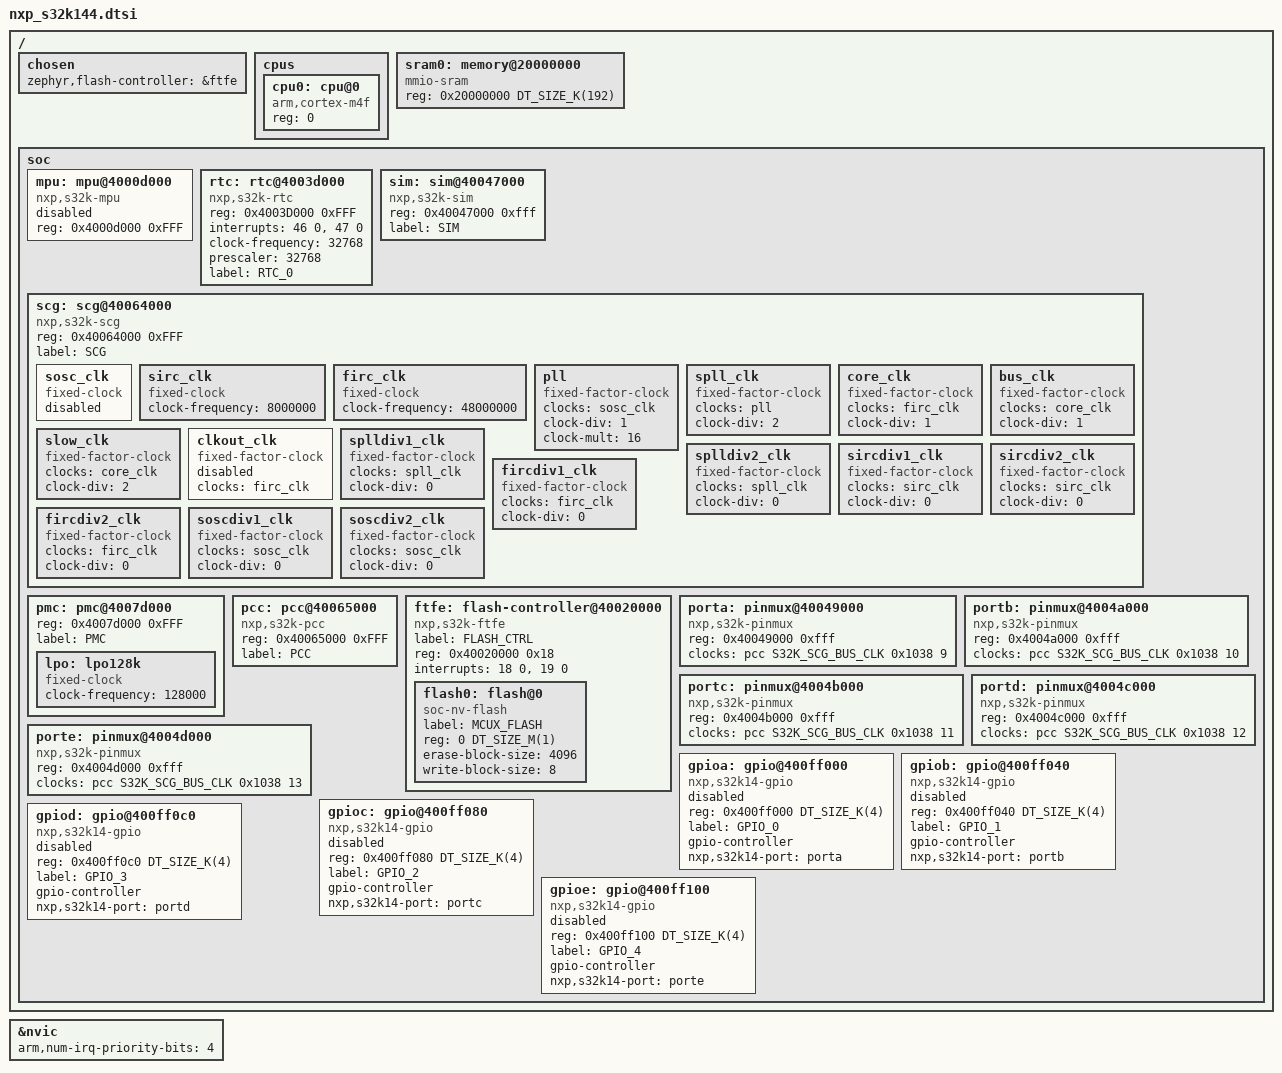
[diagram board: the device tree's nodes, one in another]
/*
 * Copyright (c) 2021, Dung Tran
 *
 * SPDX-License-Identifier: Apache-2.0
 */

#include <mem.h>
#include <arm/armv7-m.dtsi>
#include <dt-bindings/clock/s32k_clock.h>
#include <dt-bindings/gpio/gpio.h>

/ {
	chosen {
		zephyr,flash-controller = &ftfe;
	};

	cpus {
		#address-cells = <1>;
		#size-cells = <0>;

		cpu0: cpu@0 {
			device_type = "cpu";
			compatible = "arm,cortex-m4f";
			reg = <0>;
		};
	};

	sram0: memory@20000000 {
		compatible = "mmio-sram";
		reg = <0x20000000 DT_SIZE_K(192)>;
	};

	soc {
		mpu: mpu@4000d000 {
			compatible = "nxp,s32k-mpu";
			reg = <0x4000d000 0xFFF>;
			status = "disabled";
		};

		rtc: rtc@4003d000 {
			compatible = "nxp,s32k-rtc";
			reg = <0x4003D000 0xFFF>;
			interrupts = <46 0>, <47 0>;
			interrupt-names = "alarm", "seconds";
			clock-frequency = <32768>;
			prescaler = <32768>;
			label = "RTC_0";
		};

		sim: sim@40047000 {
			compatible = "nxp,s32k-sim";
			reg = <0x40047000 0xfff>;
			label = "SIM";
			#clock-cells = <3>;
		};

		scg: scg@40064000 {
			compatible = "nxp,s32k-scg";
			reg = <0x40064000 0xFFF>;
			label = "SCG";
			#clock-cells = <1>;

			sosc_clk: sosc_clk {
				compatible = "fixed-clock";
				status = "disabled";
				#clock-cells = <0>;
			};

			sirc_clk: sirc_clk {
				compatible = "fixed-clock";
				clock-frequency = <8000000>;
				#clock-cells = <0>;
			};

			firc_clk: firc_clk {
				compatible = "fixed-clock";
				clock-frequency = <48000000>;
				#clock-cells = <0>;
			};

			pll: pll {
				compatible = "fixed-factor-clock";
				clocks = <&sosc_clk>;
				clock-div = <1>;
				clock-mult = <16>;
				#clock-cells = <0>;
			};

			spll_clk: spll_clk {
				compatible = "fixed-factor-clock";
				clocks = <&pll>;
				clock-div = <2>;
				#clock-cells = <0>;
			};

			core_clk: core_clk {
				compatible = "fixed-factor-clock";
				clocks = <&firc_clk>;
				clock-div = <1>;
				#clock-cells = <0>;
			};

			bus_clk: bus_clk {
				compatible = "fixed-factor-clock";
				clocks = <&core_clk>;
				clock-div = <1>;
				#clock-cells = <0>;
			};

			slow_clk: slow_clk {
				compatible = "fixed-factor-clock";
				clocks = <&core_clk>;
				clock-div = <2>;
				#clock-cells = <0>;
			};

			clkout_clk: clkout_clk {
				compatible = "fixed-factor-clock";
				status = "disabled";
				clocks = <&firc_clk>;
				#clock-cells = <0>;
			};

			splldiv1_clk: splldiv1_clk {
				compatible = "fixed-factor-clock";
				clocks = <&spll_clk>;
				clock-div = <0>;
				#clock-cells = <0>;
			};

			splldiv2_clk: splldiv2_clk {
				compatible = "fixed-factor-clock";
				clocks = <&spll_clk>;
				clock-div = <0>;
				#clock-cells = <0>;
			};

			sircdiv1_clk: sircdiv1_clk {
				compatible = "fixed-factor-clock";
				clocks = <&sirc_clk>;
				clock-div = <0>;
				#clock-cells = <0>;
			};

			sircdiv2_clk: sircdiv2_clk {
				compatible = "fixed-factor-clock";
				clocks = <&sirc_clk>;
				clock-div = <0>;
				#clock-cells = <0>;
			};

			fircdiv1_clk: fircdiv1_clk {
				compatible = "fixed-factor-clock";
				clocks = <&firc_clk>;
				clock-div = <0>;
				#clock-cells = <0>;
			};

			fircdiv2_clk: fircdiv2_clk {
				compatible = "fixed-factor-clock";
				clocks = <&firc_clk>;
				clock-div = <0>;
				#clock-cells = <0>;
			};

			soscdiv1_clk: soscdiv1_clk {
				compatible = "fixed-factor-clock";
				clocks = <&sosc_clk>;
				clock-div = <0>;
				#clock-cells = <0>;
			};

			soscdiv2_clk: soscdiv2_clk {
				compatible = "fixed-factor-clock";
				clocks = <&sosc_clk>;
				clock-div = <0>;
				#clock-cells = <0>;
			};
		};

		pmc: pmc@4007d000 {
			reg = <0x4007d000 0xFFF>;
			label = "PMC";

			lpo: lpo128k {
			/* LPO clock */
				compatible = "fixed-clock";
				clock-frequency = <128000>;
				#clock-cells = <0>;
			};
		};

		pcc: pcc@40065000 {
			compatible = "nxp,s32k-pcc";
			reg = <0x40065000 0xFFF>;
			label = "PCC";
			#clock-cells = <2>;
		};

		ftfe: flash-controller@40020000 {
			compatible = "nxp,s32k-ftfe";
			label = "FLASH_CTRL";
			reg = <0x40020000 0x18>;
			interrupts = <18 0>, <19 0>;
			interrupt-names = "command-complete", "read-collision";

			#address-cells = <1>;
			#size-cells = <1>;

			flash0: flash@0 {
				compatible = "soc-nv-flash";
				label = "MCUX_FLASH";
				reg = <0 DT_SIZE_M(1)>;
				erase-block-size = <4096>;
				write-block-size = <8>;
			};
		};

		porta: pinmux@40049000 {
			compatible = "nxp,s32k-pinmux";
			reg = <0x40049000 0xfff>;
			clocks = <&pcc S32K_SCG_BUS_CLK 0x1038 9>;
		};

		portb: pinmux@4004a000 {
			compatible = "nxp,s32k-pinmux";
			reg = <0x4004a000 0xfff>;
			clocks = <&pcc S32K_SCG_BUS_CLK 0x1038 10>;
		};

		portc: pinmux@4004b000 {
			compatible = "nxp,s32k-pinmux";
			reg = <0x4004b000 0xfff>;
			clocks = <&pcc S32K_SCG_BUS_CLK 0x1038 11>;
		};

		portd: pinmux@4004c000 {
			compatible = "nxp,s32k-pinmux";
			reg = <0x4004c000 0xfff>;
			clocks = <&pcc S32K_SCG_BUS_CLK 0x1038 12>;
		};

		porte: pinmux@4004d000 {
			compatible = "nxp,s32k-pinmux";
			reg = <0x4004d000 0xfff>;
			clocks = <&pcc S32K_SCG_BUS_CLK 0x1038 13>;
		};

		gpioa: gpio@400ff000 {
			compatible = "nxp,s32k14-gpio";
			status = "disabled";
			reg = <0x400ff000 DT_SIZE_K(4)>;
			label = "GPIO_0";
			gpio-controller;
			#gpio-cells = <2>;
			nxp,s32k14-port = <&porta>;
		};

		gpiob: gpio@400ff040 {
			compatible = "nxp,s32k14-gpio";
			status = "disabled";
			reg = <0x400ff040 DT_SIZE_K(4)>;
			label = "GPIO_1";
			gpio-controller;
			#gpio-cells = <2>;
			nxp,s32k14-port = <&portb>;
		};

		gpioc: gpio@400ff080 {
			compatible = "nxp,s32k14-gpio";
			status = "disabled";
			reg = <0x400ff080 DT_SIZE_K(4)>;
			label = "GPIO_2";
			gpio-controller;
			#gpio-cells = <2>;
			nxp,s32k14-port = <&portc>;
		};

		gpiod: gpio@400ff0c0 {
			compatible = "nxp,s32k14-gpio";
			status = "disabled";
			reg = <0x400ff0c0 DT_SIZE_K(4)>;
			label = "GPIO_3";
			gpio-controller;
			#gpio-cells = <2>;
			nxp,s32k14-port = <&portd>;
		};

		gpioe: gpio@400ff100 {
			compatible = "nxp,s32k14-gpio";
			status = "disabled";
			reg = <0x400ff100 DT_SIZE_K(4)>;
			label = "GPIO_4";
			gpio-controller;
			#gpio-cells = <2>;
			nxp,s32k14-port = <&porte>;
		};

		// ftm0: ftm@40038000{
		// 	compatible = "nxp,s32k-ftm";
		// 	reg = <0x40038000 0xFFF>;
		// 	interrupts = <42 0>;
		// 	clocks = <&pcc KINETIS_MCG_FIXED_FREQ_CLK>;
		// 	prescaler = <16>;
		// 	label = "FTM_0";
		// 	status = "disabled";
		// };

		// ftm1: ftm@40039000{
		// 	compatible = "nxp,s32k-ftm";
		// 	reg = <0x40039000 0xFFF>;
		// 	interrupts = <42 0>;
		// 	clocks = <&pcc KINETIS_MCG_FIXED_FREQ_CLK>;
		// 	prescaler = <16>;
		// 	label = "FTM_1";
		// 	status = "disabled";
		// };

		// ftm2: ftm@4003A000{
		// 	compatible = "nxp,s32k-ftm";
		// 	reg = <0x4003A000 0xFFF>;
		// 	interrupts = <42 0>;
		// 	clocks = <&pcc KINETIS_MCG_FIXED_FREQ_CLK>;
		// 	prescaler = <16>;
		// 	label = "FTM_2";
		// 	status = "disabled";
		// };

		// ftm3: ftm@40026000{
		// 	compatible = "nxp,s32k-ftm";
		// 	reg = <0x40026000 0xFFF>;
		// 	interrupts = <42 0>;
		// 	clocks = <&pcc KINETIS_MCG_FIXED_FREQ_CLK>;
		// 	prescaler = <16>;
		// 	label = "FTM_3";
		// 	status = "disabled";
		// };

		// lpuart0: uart@4006A000 {
		// 	compatible = "nxp,s32k-linflex";
		// 	reg = <0x4006A000 0xFFF>;
		// 	interrupts = <20 0>;
		// 	interrupt-names = "transmit", "receive";
		// 	clocks = <&pcc IMX_CCM_LPUART1_CLK 0x7c 24>;
		// 	label = "UART_0";
		// 	status = "disabled";
		// };

		// lpuart1: uart@4006B000 {
		// 	compatible = "nxp,s32k-linflex";
		// 	reg = <0x4006B000 0xFFF>;
		// 	interrupts = <20 0>;
		// 	interrupt-names = "transmit", "receive";
		// 	clocks = <&pcc IMX_CCM_LPUART1_CLK 0x7c 24>;
		// 	label = "UART_1";
		// 	status = "disabled";
		// };

		// lpspi0: spi@4002C000 {
		// 	compatible = "nxp,s32k-lpspi";
		// 	reg = <0x4002C000 0xFFF>;
		// 	interrupts = <130 0>;
		// 	clocks = <&pcc 0xb0 KINETIS_PCC_SRC_FIRC_ASYNC>;
		// 	label = "LPSPI0";
		// 	status = "disabled";
		// 	#address-cells = <1>;
		// 	#size-cells = <0>;
		// };

		// lpspi1: spi@4002D000 {
		// 	compatible = "nxp,s32k-lpspi";
		// 	reg = <0x4002D000 0xFFF>;
		// 	interrupts = <130 0>;
		// 	clocks = <&pcc 0xb0 KINETIS_PCC_SRC_FIRC_ASYNC>;
		// 	label = "LPSPI0";
		// 	status = "disabled";
		// 	#address-cells = <1>;
		// 	#size-cells = <0>;
		// };

		// lpspi2: spi@4002E000 {
		// 	compatible = "nxp,s32k-lpspi";
		// 	reg = <0x4002E000 0xFFF>;
		// 	interrupts = <130 0>;
		// 	clocks = <&pcc 0xb0 KINETIS_PCC_SRC_FIRC_ASYNC>;
		// 	label = "LPSPI0";
		// 	status = "disabled";
		// 	#address-cells = <1>;
		// 	#size-cells = <0>;
		// };

		// flexcan0: can@40024000 {
		// 	compatible = "nxp,s32k-flexcan";
		// 	reg = <0x40024000 0xFFF>;
		// 	interrupts = <44 0>, <45 0>;
		// 	interrupt-names = "common", "error";
		// 	clocks = <&scg S32K_SCG_BUS_CLK>;
		// 	clk-source = <2>;
		// 	label = "CAN_1";
		// 	sjw = <1>;
		// 	prop-seg = <1>;
		// 	phase-seg1 = <3>;
		// 	phase-seg2 = <2>;
		// 	status = "disabled";
		// 	#address-cells = <1>;
		// 	#size-cells = <0>;
		// };

		// flexcan1: can@40024000 {
		// 	compatible = "nxp,s32k-flexcan";
		// 	reg = <0x40024000 0xFFF>;
		// 	interrupts = <44 0>, <45 0>;
		// 	interrupt-names = "common", "error";
		// 	clocks = <&scg S32K_SCG_BUS_CLK 0x68 14>;
		// 	clk-source = <2>;
		// 	label = "CAN_1";
		// 	sjw = <1>;
		// 	prop-seg = <1>;
		// 	phase-seg1 = <3>;
		// 	phase-seg2 = <2>;
		// 	status = "disabled";
		// 	#address-cells = <1>;
		// 	#size-cells = <0>;
		// };

		// flexcan2: can@40024000 {
		// 	compatible = "nxp,s32k-flexcan";
		// 	reg = <0x40024000 0xFFF>;
		// 	interrupts = <44 0>, <45 0>;
		// 	interrupt-names = "common", "error";
		// 	clocks = <&scg S32K_SCG_BUS_CLK 0x68 14>;
		// 	clk-source = <2>;
		// 	label = "CAN_1";
		// 	sjw = <1>;
		// 	prop-seg = <1>;
		// 	phase-seg1 = <3>;
		// 	phase-seg2 = <2>;
		// 	status = "disabled";
		// 	#address-cells = <1>;
		// 	#size-cells = <0>;
		// };

		// adc0: adc@4003B000 {
		// 	compatible = "nxp,s32k-adc";
		// 	reg = <0x4003B000 0xFFF>;
		// 	interrupts = <39 0>;
		// 	clocks = <&pcc 0xec KINETIS_PCC_SRC_FIRC_ASYNC>;
		// 	label = "ADC_0";
		// 	clk-source = <0>;
		// 	clk-divider = <1>;
		// 	status = "disabled";
		// 	#io-channel-cells = <1>;
		// }

		// adc1: adc@40027000 {
		// 	compatible = "nxp,s32k-adc";
		// 	reg = <0x40027000 0xFFF>;
		// 	interrupts = <39 0>;
		// 	clocks = <&pcc 0xec KINETIS_PCC_SRC_FIRC_ASYNC>;
		// 	label = "ADC_0";
		// 	clk-source = <0>;
		// 	clk-divider = <1>;
		// 	status = "disabled";
		// 	#io-channel-cells = <1>;
		// }

		// wdog: wdog@40052000 {
		// 	compatible = "nxp,s32k-wdog";
		// 	reg = <0x40052000 0xFFF>;
		// 	status = "disabled";
		// 	interrupts = <112 0>;
		// 	label = "WDOG";
		// };

		// pit0: pit@40037000 {
		// 	compatible = "nxp,s32k-pit";
		// 	reg = <0x40037000 0xFFF>;
		// 	clocks = <&sim KINETIS_SIM_BUS_CLK 0x103c 23>;
		// 	interrupts = <48 0>, <49 0>, <50 0>, <51 0>;
		// 	status = "disabled";
		// 	pit-channel = <0>;
		// 	pit-period = <1000000>;
		// 	clock-frequency = <60000000>;
		// 	label = "PIT0";
		// };

	};
};

&nvic {
	arm,num-irq-priority-bits = <4>;
};
